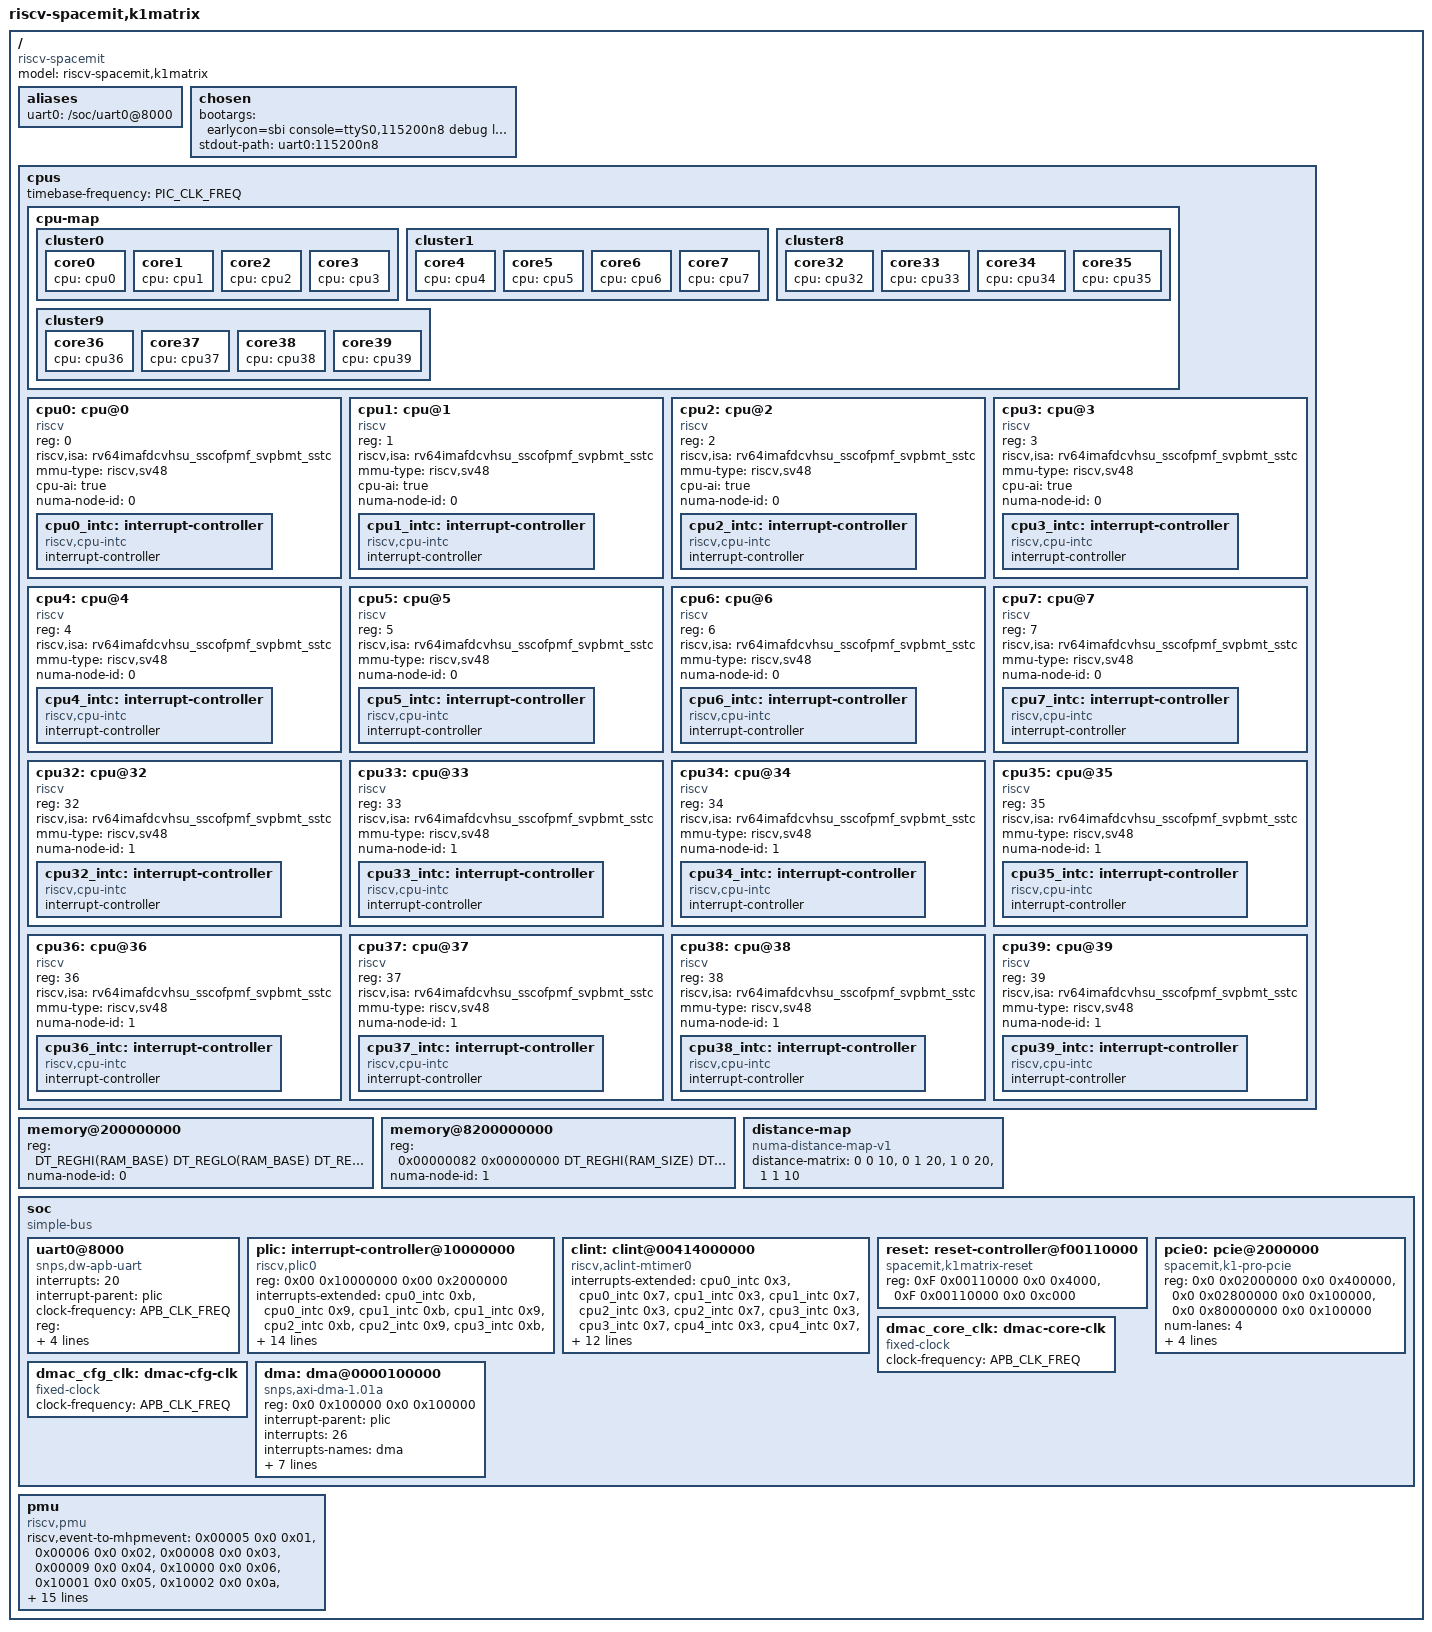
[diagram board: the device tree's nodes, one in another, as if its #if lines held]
#include <target/arch.h>
#include <dt-bindings/clock/sbi-clock-k1matrix.h>

/dts-v1/;

/memreserve/ RAM_BASE 0x02000000;

/ {
	#address-cells = <0x2>;
	#size-cells = <0x2>;
	compatible = "riscv-spacemit";
	model = "riscv-spacemit,k1matrix";

	aliases {
		uart0 = "/soc/uart0@8000";
	};

	chosen {
#ifdef CONFIG_K1MATRIX_UART_DTS_CON
		bootargs = "earlycon=sbi console=ttyS0,115200n8 debug loglevel=8,initcall_debug=1 rdinit=/sdfirm_init";
		stdout-path = "uart0:115200n8";
#else
		bootargs = "console=hvc0 earlycon=sbi rdinit=/sdfirm_init";
#endif
	};

	cpus {
		#address-cells = <0x1>;
		#size-cells = <0x0>;
		timebase-frequency = <PIC_CLK_FREQ>;

		cpu-map {
			cluster0 {
				core0 {
					cpu = <&cpu0>;
				};
#ifdef CONFIG_SMP
				core1 {
					cpu = <&cpu1>;
				};
#endif
#if CONFIG_K1MATRIX_SMP_CPUS >= 4
				core2 {
					cpu = <&cpu2>;
				};
				core3 {
					cpu = <&cpu3>;
				};
#endif
			};
#if CONFIG_K1MATRIX_SMP_CPUS >= 8
			cluster1 {
				core4 {
					cpu = <&cpu4>;
				};
				core5 {
					cpu = <&cpu5>;
				};
				core6 {
					cpu = <&cpu6>;
				};
				core7 {
					cpu = <&cpu7>;
				};
			};
#endif

#if CONFIG_K1MATRIX_SMP_CPUS >= 32
			cluster8 {
				core32 {
					cpu = <&cpu32>;
				};
				core33 {
					cpu = <&cpu33>;
				};
				core34 {
					cpu = <&cpu34>;
				};
				core35 {
					cpu = <&cpu35>;
				};
			};
			cluster9 {
				core36 {
					cpu = <&cpu36>;
				};
				core37 {
					cpu = <&cpu37>;
				};
				core38 {
					cpu = <&cpu38>;
				};
				core39 {
					cpu = <&cpu39>;
				};
			};
#endif
		};

		cpu0: cpu@0 {
			device_type = "cpu";
			reg = <0>;
			status = "okay";
			compatible = "riscv";
			riscv,isa = "rv64imafdcvhsu_sscofpmf_svpbmt_sstc";
			mmu-type = "riscv,sv48";
			cpu-ai = "true";
			numa-node-id = <0>;

			cpu0_intc: interrupt-controller {
				#interrupt-cells = <0x1>;
				interrupt-controller;
				compatible = "riscv,cpu-intc";
			};
		};
#ifdef CONFIG_SMP
		cpu1: cpu@1 {
			device_type = "cpu";
			reg = <1>;
			status = "okay";
			compatible = "riscv";
			riscv,isa = "rv64imafdcvhsu_sscofpmf_svpbmt_sstc";
			mmu-type = "riscv,sv48";
			cpu-ai = "true";
			numa-node-id = <0>;

			cpu1_intc: interrupt-controller {
				#interrupt-cells = <0x1>;
				interrupt-controller;
				compatible = "riscv,cpu-intc";
			};
		};
#endif
#if CONFIG_K1MATRIX_SMP_CPUS >= 4
		cpu2: cpu@2 {
			device_type = "cpu";
			reg = <2>;
			status = "okay";
			compatible = "riscv";
			riscv,isa = "rv64imafdcvhsu_sscofpmf_svpbmt_sstc";
			mmu-type = "riscv,sv48";
			cpu-ai = "true";
			numa-node-id = <0>;

			cpu2_intc: interrupt-controller {
				#interrupt-cells = <0x1>;
				interrupt-controller;
				compatible = "riscv,cpu-intc";
			};
		};
		cpu3: cpu@3 {
			device_type = "cpu";
			reg = <3>;
			status = "okay";
			compatible = "riscv";
			riscv,isa = "rv64imafdcvhsu_sscofpmf_svpbmt_sstc";
			mmu-type = "riscv,sv48";
			cpu-ai = "true";
			numa-node-id = <0>;

			cpu3_intc: interrupt-controller {
				#interrupt-cells = <0x1>;
				interrupt-controller;
				compatible = "riscv,cpu-intc";
			};
		};
#endif
#if CONFIG_K1MATRIX_SMP_CPUS >= 8
		cpu4: cpu@4 {
			device_type = "cpu";
			reg = <4>;
			status = "okay";
			compatible = "riscv";
			riscv,isa = "rv64imafdcvhsu_sscofpmf_svpbmt_sstc";
			mmu-type = "riscv,sv48";
			numa-node-id = <0>;

			cpu4_intc: interrupt-controller {
				#interrupt-cells = <0x1>;
				interrupt-controller;
				compatible = "riscv,cpu-intc";
			};
		};
		cpu5: cpu@5 {
			device_type = "cpu";
			reg = <5>;
			status = "okay";
			compatible = "riscv";
			riscv,isa = "rv64imafdcvhsu_sscofpmf_svpbmt_sstc";
			mmu-type = "riscv,sv48";
			numa-node-id = <0>;

			cpu5_intc: interrupt-controller {
				#interrupt-cells = <0x1>;
				interrupt-controller;
				compatible = "riscv,cpu-intc";
			};
		};
		cpu6: cpu@6 {
			device_type = "cpu";
			reg = <6>;
			status = "okay";
			compatible = "riscv";
			riscv,isa = "rv64imafdcvhsu_sscofpmf_svpbmt_sstc";
			mmu-type = "riscv,sv48";
			numa-node-id = <0>;

			cpu6_intc: interrupt-controller {
				#interrupt-cells = <0x1>;
				interrupt-controller;
				compatible = "riscv,cpu-intc";
			};
		};
		cpu7: cpu@7 {
			device_type = "cpu";
			reg = <7>;
			status = "okay";
			compatible = "riscv";
			riscv,isa = "rv64imafdcvhsu_sscofpmf_svpbmt_sstc";
			mmu-type = "riscv,sv48";
			numa-node-id = <0>;

			cpu7_intc: interrupt-controller {
				#interrupt-cells = <0x1>;
				interrupt-controller;
				compatible = "riscv,cpu-intc";
			};
		};
#endif

#if CONFIG_K1MATRIX_SMP_CPUS >= 32
		cpu32: cpu@32 {
			device_type = "cpu";
			reg = <32>;
			status = "okay";
			compatible = "riscv";
			riscv,isa = "rv64imafdcvhsu_sscofpmf_svpbmt_sstc";
			mmu-type = "riscv,sv48";
			numa-node-id = <1>;

			cpu32_intc: interrupt-controller {
				#interrupt-cells = <0x1>;
				interrupt-controller;
				compatible = "riscv,cpu-intc";
			};
		};
		cpu33: cpu@33 {
			device_type = "cpu";
			reg = <33>;
			status = "okay";
			compatible = "riscv";
			riscv,isa = "rv64imafdcvhsu_sscofpmf_svpbmt_sstc";
			mmu-type = "riscv,sv48";
			numa-node-id = <1>;

			cpu33_intc: interrupt-controller {
				#interrupt-cells = <0x1>;
				interrupt-controller;
				compatible = "riscv,cpu-intc";
			};
		};
		cpu34: cpu@34 {
			device_type = "cpu";
			reg = <34>;
			status = "okay";
			compatible = "riscv";
			riscv,isa = "rv64imafdcvhsu_sscofpmf_svpbmt_sstc";
			mmu-type = "riscv,sv48";
			numa-node-id = <1>;

			cpu34_intc: interrupt-controller {
				#interrupt-cells = <0x1>;
				interrupt-controller;
				compatible = "riscv,cpu-intc";
			};
		};
		cpu35: cpu@35 {
			device_type = "cpu";
			reg = <35>;
			status = "okay";
			compatible = "riscv";
			riscv,isa = "rv64imafdcvhsu_sscofpmf_svpbmt_sstc";
			mmu-type = "riscv,sv48";
			numa-node-id = <1>;

			cpu35_intc: interrupt-controller {
				#interrupt-cells = <0x1>;
				interrupt-controller;
				compatible = "riscv,cpu-intc";
			};
		};
		cpu36: cpu@36 {
			device_type = "cpu";
			reg = <36>;
			status = "okay";
			compatible = "riscv";
			riscv,isa = "rv64imafdcvhsu_sscofpmf_svpbmt_sstc";
			mmu-type = "riscv,sv48";
			numa-node-id = <1>;

			cpu36_intc: interrupt-controller {
				#interrupt-cells = <0x1>;
				interrupt-controller;
				compatible = "riscv,cpu-intc";
			};
		};
		cpu37: cpu@37 {
			device_type = "cpu";
			reg = <37>;
			status = "okay";
			compatible = "riscv";
			riscv,isa = "rv64imafdcvhsu_sscofpmf_svpbmt_sstc";
			mmu-type = "riscv,sv48";
			numa-node-id = <1>;

			cpu37_intc: interrupt-controller {
				#interrupt-cells = <0x1>;
				interrupt-controller;
				compatible = "riscv,cpu-intc";
			};
		};
		cpu38: cpu@38 {
			device_type = "cpu";
			reg = <38>;
			status = "okay";
			compatible = "riscv";
			riscv,isa = "rv64imafdcvhsu_sscofpmf_svpbmt_sstc";
			mmu-type = "riscv,sv48";
			numa-node-id = <1>;

			cpu38_intc: interrupt-controller {
				#interrupt-cells = <0x1>;
				interrupt-controller;
				compatible = "riscv,cpu-intc";
			};
		};
		cpu39: cpu@39 {
			device_type = "cpu";
			reg = <39>;
			status = "okay";
			compatible = "riscv";
			riscv,isa = "rv64imafdcvhsu_sscofpmf_svpbmt_sstc";
			mmu-type = "riscv,sv48";
			numa-node-id = <1>;

			cpu39_intc: interrupt-controller {
				#interrupt-cells = <0x1>;
				interrupt-controller;
				compatible = "riscv,cpu-intc";
			};
		};
#endif
	};

	memory@200000000 {
		device_type = "memory";
		reg = <DT_REGHI(RAM_BASE) DT_REGLO(RAM_BASE)
		       DT_REGHI(RAM_SIZE) DT_REGLO(RAM_SIZE)
		>;
		numa-node-id = <0>;
	};

#if CONFIG_K1MATRIX_D2D >= 32
	memory@8200000000 {
		device_type = "memory";
		reg = <0x00000082 0x00000000
		       DT_REGHI(RAM_SIZE) DT_REGLO(RAM_SIZE)
		>;
		numa-node-id = <1>;
	};

	distance-map {
		compatible = "numa-distance-map-v1";
		distance-matrix = <0 0	10>,
				  <0 1	20>,
				  <1 0	20>,
				  <1 1	10>;
	};
#endif

	soc {
		#address-cells = <0x2>;
		#size-cells = <0x2>;
		compatible = "simple-bus";
		ranges;

		uart0@8000 {
			interrupts = <20>;
			interrupt-parent = <&plic>;
			clock-frequency = <APB_CLK_FREQ>;
			reg = <DT_REGHI(__UART0_BASE) DT_REGLO(__UART0_BASE)
			       0x0 0x1000
			>;
			reg-io-width = <4>;
			reg-shift = <2>;
			hw-flow-control = "unsupport";
			compatible = "snps,dw-apb-uart";
#ifdef CONFIG_K1MATRIX_UART_DTS_CON
			status = "okay";
#else
			status = "disabled";
#endif
		};

		plic: interrupt-controller@10000000 {
			reg = <0x00 0x10000000 0x00 0x2000000>;
			//reg = <DT_REGHI(PLIC_REG_BASE) DT_REGLO(PLIC_REG_BASE)
			//        0x0 0x08000000
			// >;
			interrupts-extended = <
				&cpu0_intc 0xb &cpu0_intc 0x9
#ifdef CONFIG_SMP
				&cpu1_intc 0xb &cpu1_intc 0x9
#endif
#if CONFIG_K1MATRIX_SMP_CPUS >= 4
				&cpu2_intc 0xb &cpu2_intc 0x9
				&cpu3_intc 0xb &cpu3_intc 0x9
#endif
#if CONFIG_K1MATRIX_SMP_CPUS >= 8
				&cpu4_intc 0xb &cpu4_intc 0x9
				&cpu5_intc 0xb &cpu5_intc 0x9
				&cpu6_intc 0xb &cpu6_intc 0x9
				&cpu7_intc 0xb &cpu7_intc 0x9
#endif
#if CONFIG_K1MATRIX_SMP_CPUS >= 32
				&cpu32_intc 0xb &cpu32_intc 0x9
				&cpu33_intc 0xb &cpu33_intc 0x9
				&cpu34_intc 0xb &cpu34_intc 0x9
				&cpu35_intc 0xb &cpu35_intc 0x9
				&cpu36_intc 0xb &cpu36_intc 0x9
				&cpu37_intc 0xb &cpu37_intc 0x9
				&cpu38_intc 0xb &cpu38_intc 0x9
				&cpu39_intc 0xb &cpu39_intc 0x9
#endif
			>;
			interrupt-controller;
			riscv,ndev = <39>;
			riscv,max-priority = <7>;
			compatible = "riscv,plic0";
			#interrupt-cells = <0x1>;
			#address-cells = <0x0>;
		};

		clint: clint@00414000000 {
			interrupts-extended = <
				&cpu0_intc 0x3 &cpu0_intc 0x7
#ifdef CONFIG_SMP
				&cpu1_intc 0x3 &cpu1_intc 0x7
#endif
#if CONFIG_K1MATRIX_SMP_CPUS >= 4
				&cpu2_intc 0x3 &cpu2_intc 0x7
				&cpu3_intc 0x3 &cpu3_intc 0x7
#endif
#if CONFIG_K1MATRIX_SMP_CPUS >= 8
				&cpu4_intc 0x3 &cpu4_intc 0x7
				&cpu5_intc 0x3 &cpu5_intc 0x7
				&cpu6_intc 0x3 &cpu6_intc 0x7
				&cpu7_intc 0x3 &cpu7_intc 0x7
#endif
#if CONFIG_K1MATRIX_SMP_CPUS >= 32
				&cpu32_intc 0x3 &cpu32_intc 0x7
				&cpu33_intc 0x3 &cpu33_intc 0x7
				&cpu34_intc 0x3 &cpu34_intc 0x7
				&cpu35_intc 0x3 &cpu35_intc 0x7
				&cpu36_intc 0x3 &cpu36_intc 0x7
				&cpu37_intc 0x3 &cpu37_intc 0x7
				&cpu38_intc 0x3 &cpu38_intc 0x7
				&cpu39_intc 0x3 &cpu39_intc 0x7
#endif
			>;
			reg = <DT_REGHI(__RMU_CLINT_BASE) DT_REGLO(__RMU_CLINT_BASE)
			       0x0 0x00010000
			>;
#ifdef CONFIG_ACLINT_DT
			compatible = "riscv,aclint-mtimer0";
#else
			compatible = "riscv,clint0";
#ifdef CONFIG_ARCH_IS_MMIO_32BIT
			clint,has-no-64bit-mmio;
#endif
#endif
		};

		reset: reset-controller@f00110000 {
			#address-cells = <0x1>;
			#size-cells = <0x1>;
			compatible = "spacemit,k1matrix-reset";
			reg = <0xF 0x00110000 0x0 0x4000>, <0xF 0x00110000 0x0 0xc000>;
			#reset-cells = <1>;
			status = "okay";
		};

		pcie0: pcie@2000000 {
			compatible = "spacemit,k1-pro-pcie";
			reg = <0x0 0x02000000 0x0 0x400000>,
			      <0x0 0x02800000 0x0 0x100000>,
			      <0x0 0x80000000 0x0 0x100000>;
			reg-names = "dbi", "app", "config";
			num-lanes = <4>;
			device_type = "pci";

			#address-cells = <3>;
			#size-cells = <2>;
			ranges = <0x81000000 0 0x80100000 0 0x80100000 0 0x00100000>,   /* downstream I/O */
			         <0x82000000 0 0x80200000 0 0x80200000 0 0x05e00000>,   /* non-prefetchable memory */
			         <0xc3000000 0 0x86000000 0 0x86000000 0 0x02000000>;   /* mem prefetchable */
			bus-range = <0x00 0xff>;

			interrupt-parent = <&plic>;
			interrupts = <30>;
			interrupt-names = "msi";

			resets = <&reset 0>,
			         <&reset 1>,
			         <&reset 2>;
			reset-names = "cold", "button", "warm";
			status = "okay";
		};

		dmac_core_clk: dmac-core-clk {
			compatible = "fixed-clock";
			clock-frequency = <APB_CLK_FREQ>;
			#clock-cells = <0>;
		};

		dmac_cfg_clk: dmac-cfg-clk {
			compatible = "fixed-clock";
			clock-frequency = <APB_CLK_FREQ>;
			#clock-cells = <0>;
		};

		dma: dma@0000100000 {
			compatible = "snps,axi-dma-1.01a";
			reg = < 0x0 0x100000 0x0 0x100000 >;
			interrupt-parent = <&plic>;
			interrupts = <26>;
			interrupts-names = "dma";
			clocks = <&dmac_core_clk>, <&dmac_cfg_clk>;
			clock-names = "core-clk", "cfgr-clk";
			dma-channels = <2>;
			snps,dma-masters = <1>;
			snps,data-width = <4>;
			snps,block-size = <0x200000 0x200000>;
			snps,priority = <0 1>;
			snps,axi-max-burst-len = <16 16>;
			#dma-cells = <1>;
			status = "okay";
		};
	};

	pmu {
		compatible = "riscv,pmu";

		riscv,event-to-mhpmevent =
			/* BRANCH_INSTRUCTIONS */
			<0x00005 0x0 0x01>,
			/* BRANCH_MISSES */
			<0x00006 0x0 0x02>,
			/* STALLED_CYCLES_FRONTEND */
			<0x00008 0x0 0x03>,
			/* STALLED_CYCLES_BACKEND */
			<0x00009 0x0 0x04>,
			/* L1D_READ_ACCESS */
			<0x10000 0x0 0x06>,
			/* L1D_READ_MISS */
			<0x10001 0x0 0x05>,
			/* L1D_WRITE_ACCESS */
			<0x10002 0x0 0x0a>,
			/* L1D_WRITE_MISS */
			<0x10003 0x0 0x09>,
			/* L1I_READ_ACCESS */
			<0x10008 0x0 0x0c>,
			/* L1I_READ_MISS */
			<0x10009 0x0 0x0b>,
			/* L1I_PREFETCH_ACCESS */
			<0x1000c 0x0 0x0e>,
			/* L1I_PREFETCH_MISS */
			<0x1000d 0x0 0x0d>,
			/* DTLB_READ_MISS */
			<0x10019 0x0 0x15>,
			/* DTLB_WRITE_MISS */
			<0x1001b 0x0 0x19>,
			/* ITLB_READ_MISS */
			<0x10021 0x0 0x1b>;

		/* 16 valid counters: mhpmcounter3 ~ mhpmcounter18 */
		riscv,event-to-mhpmcounters =
			<0x00005 0x00006 0x0007fff8>,
			<0x00008 0x00009 0x0007fff8>,
			<0x10000 0x10003 0x0007fff8>,
			<0x10008 0x10009 0x0007fff8>,
			<0x1000c 0x1000d 0x0007fff8>,
			<0x10019 0x10019 0x0007fff8>,
			<0x1001b 0x1001b 0x0007fff8>,
			<0x10021 0x10021 0x0007fff8>;

		riscv,raw-event-to-mhpmcounters =
			/*
			 * For convenience, we treat 0x1~0xff as valid indexes,
			 * but actually in hardware the valid indexes are 0x1~0xbd.
			 */
			<0x0 0x0 0xffffffff 0xffffff00 0x0007fff8>;
	};
};
